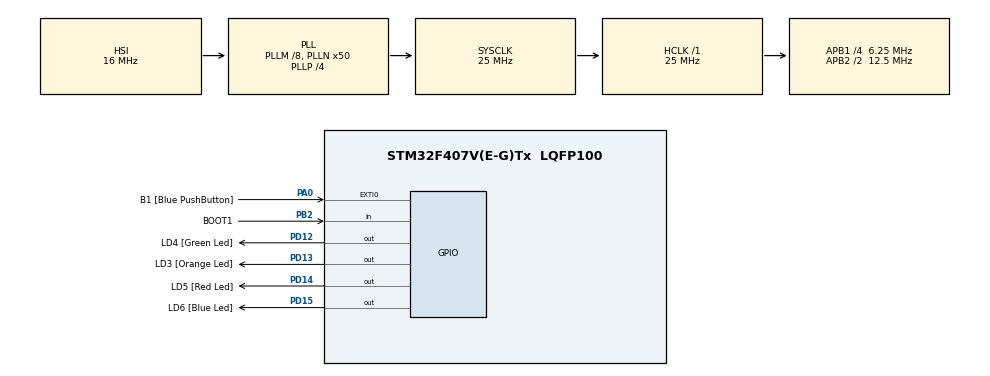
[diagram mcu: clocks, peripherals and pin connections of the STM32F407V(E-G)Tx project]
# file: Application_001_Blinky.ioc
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Mcu.Family=STM32F4
Mcu.Name=STM32F407V(E-G)Tx
Mcu.Package=LQFP100
NVIC.PriorityGroup=NVIC_PRIORITYGROUP_4
NVIC.TIM6_DAC_IRQn=true\:0\:0\:false\:false\:true\:false\:true\:true
NVIC.TimeBase=TIM6_DAC_IRQn
NVIC.TimeBaseIP=TIM6
PA0-WKUP.GPIO_Label=B1 [Blue PushButton]
PA0-WKUP.Signal=GPXTI0
PA13.GPIO_Label=SWDIO
PA13.Signal=SYS_JTMS-SWDIO
PA14.GPIO_Label=SWCLK
PA14.Signal=SYS_JTCK-SWCLK
PB2.GPIO_Label=BOOT1
PB2.GPIO_Mode=GPIO_MODE_INPUT
PB2.GPIO_PuPd=GPIO_NOPULL
PB2.Signal=GPIO_Input
PB3.GPIO_Label=SWO
PB3.Signal=SYS_JTDO-SWO
PC7.GPIO_Label=I2S3_MCK [CS43L22_MCLK]
PC7.GPIO_Mode=GPIO_MODE_AF_PP
PC7.GPIO_PuPd=GPIO_NOPULL
PC7.GPIO_Speed=GPIO_SPEED_FREQ_LOW
PC7.Signal=I2S3_MCK
PD12.GPIO_Label=LD4 [Green Led]
PD12.GPIO_PuPd=GPIO_NOPULL
PD12.GPIO_Speed=GPIO_SPEED_FREQ_LOW
PD12.Signal=GPIO_Output
PD13.GPIO_Label=LD3 [Orange Led]
PD13.GPIO_PuPd=GPIO_NOPULL
PD13.GPIO_Speed=GPIO_SPEED_FREQ_LOW
PD13.Signal=GPIO_Output
PD14.GPIO_Label=LD5 [Red Led]
PD14.GPIO_PuPd=GPIO_NOPULL
PD14.GPIO_Speed=GPIO_SPEED_FREQ_LOW
PD14.Signal=GPIO_Output
PD15.GPIO_Label=LD6 [Blue Led]
PD15.GPIO_PuPd=GPIO_NOPULL
PD15.GPIO_Speed=GPIO_SPEED_FREQ_LOW
PD15.Signal=GPIO_Output
ProjectManager.HeapSize=0x200
ProjectManager.StackSize=0x400
ProjectManager.TargetToolchain=STM32CubeIDE
RCC.48MHZClocksFreq_Value=14285714.285714285
RCC.AHBFreq_Value=25000000
RCC.APB1CLKDivider=RCC_HCLK_DIV4
RCC.APB1Freq_Value=6250000
RCC.APB1TimFreq_Value=12500000
RCC.APB2CLKDivider=RCC_HCLK_DIV2
RCC.APB2Freq_Value=12500000
RCC.APB2TimFreq_Value=25000000
RCC.CortexFreq_Value=25000000
RCC.HCLKFreq_Value=25000000
RCC.HSE_VALUE=8000000
RCC.HSI_VALUE=16000000
RCC.LSE_VALUE=32768
RCC.PLLM=8
RCC.PLLN=50
RCC.PLLP=RCC_PLLP_DIV4
RCC.PLLQ=7
RCC.SYSCLKFreq_VALUE=25000000
RCC.SYSCLKSource=RCC_SYSCLKSOURCE_PLLCLK
RCC.VCOOutputFreq_Value=100000000
VP_SYS_VS_tim6.Mode=TIM6
board=STM32F407G-DISC1

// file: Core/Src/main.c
/* USER CODE BEGIN Header */
/**
  ******************************************************************************
  * @file           : main.c
  * @brief          : Main program body
  ******************************************************************************
  * @attention
  *
  * Copyright (c) 2024 STMicroelectronics.
  * All rights reserved.
  *
  * This software is licensed under terms that can be found in the LICENSE file
  * in the root directory of this software component.
  * If no LICENSE file comes with this software, it is provided AS-IS.
  *
  ******************************************************************************
  */
/* USER CODE END Header */
#include "main.h"

/* USER CODE BEGIN Includes */
#include "FreeRTOS.h"
#include "task.h"
/* USER CODE END Includes */

void SystemClock_Config(void);
static void MX_GPIO_Init(void);
/* USER CODE BEGIN PFP */
void LED_Task( void *pvParameters );
/* USER CODE END PFP */

int main(void)
{

  /* MCU Configuration--------------------------------------------------------*/

  /* Reset of all peripherals, Initializes the Flash interface and the Systick. */
  HAL_Init();

  /* Configure the system clock */
  SystemClock_Config();

  /* Initialize all configured peripherals */
  MX_GPIO_Init();
  /* USER CODE BEGIN 2 */
  xTaskCreate( LED_Task, "LED", 128, NULL, 1, NULL );
  vTaskStartScheduler();
  /* USER CODE END 2 */

  /* Infinite loop */
  while (1)
  {

  }
}

void SystemClock_Config(void)
{
  RCC_OscInitTypeDef RCC_OscInitStruct = {0};
  RCC_ClkInitTypeDef RCC_ClkInitStruct = {0};

  /** Configure the main internal regulator output voltage
  */
  __HAL_RCC_PWR_CLK_ENABLE();
  __HAL_PWR_VOLTAGESCALING_CONFIG(PWR_REGULATOR_VOLTAGE_SCALE1);

  /** Initializes the RCC Oscillators according to the specified parameters
  * in the RCC_OscInitTypeDef structure.
  */
  RCC_OscInitStruct.OscillatorType = RCC_OSCILLATORTYPE_HSI;
  RCC_OscInitStruct.HSIState = RCC_HSI_ON;
  RCC_OscInitStruct.HSICalibrationValue = RCC_HSICALIBRATION_DEFAULT;
  RCC_OscInitStruct.PLL.PLLState = RCC_PLL_ON;
  RCC_OscInitStruct.PLL.PLLSource = RCC_PLLSOURCE_HSI;
  RCC_OscInitStruct.PLL.PLLM = 8;
  RCC_OscInitStruct.PLL.PLLN = 50;
  RCC_OscInitStruct.PLL.PLLP = RCC_PLLP_DIV4;
  RCC_OscInitStruct.PLL.PLLQ = 7;
  if (HAL_RCC_OscConfig(&RCC_OscInitStruct) != HAL_OK)
  {
    Error_Handler();
  }

  /** Initializes the CPU, AHB and APB buses clocks
  */
  RCC_ClkInitStruct.ClockType = RCC_CLOCKTYPE_HCLK|RCC_CLOCKTYPE_SYSCLK
                              |RCC_CLOCKTYPE_PCLK1|RCC_CLOCKTYPE_PCLK2;
  RCC_ClkInitStruct.SYSCLKSource = RCC_SYSCLKSOURCE_PLLCLK;
  RCC_ClkInitStruct.AHBCLKDivider = RCC_SYSCLK_DIV1;
  RCC_ClkInitStruct.APB1CLKDivider = RCC_HCLK_DIV4;
  RCC_ClkInitStruct.APB2CLKDivider = RCC_HCLK_DIV2;

  if (HAL_RCC_ClockConfig(&RCC_ClkInitStruct, FLASH_LATENCY_0) != HAL_OK)
  {
    Error_Handler();
  }
}

static void MX_GPIO_Init(void)
{
  GPIO_InitTypeDef GPIO_InitStruct = {0};

  /* GPIO Ports Clock Enable */
  __HAL_RCC_GPIOA_CLK_ENABLE();
  __HAL_RCC_GPIOB_CLK_ENABLE();
  __HAL_RCC_GPIOD_CLK_ENABLE();
  __HAL_RCC_GPIOC_CLK_ENABLE();

  /*Configure GPIO pin Output Level */
  HAL_GPIO_WritePin(GPIOD, LD4_Pin|LD3_Pin|LD5_Pin|LD6_Pin, GPIO_PIN_RESET);

  /*Configure GPIO pin : B1_Pin */
  GPIO_InitStruct.Pin = B1_Pin;
  GPIO_InitStruct.Mode = GPIO_MODE_IT_RISING;
  GPIO_InitStruct.Pull = GPIO_NOPULL;
  HAL_GPIO_Init(B1_GPIO_Port, &GPIO_InitStruct);

  /*Configure GPIO pin : BOOT1_Pin */
  GPIO_InitStruct.Pin = BOOT1_Pin;
  GPIO_InitStruct.Mode = GPIO_MODE_INPUT;
  GPIO_InitStruct.Pull = GPIO_NOPULL;
  HAL_GPIO_Init(BOOT1_GPIO_Port, &GPIO_InitStruct);

  /*Configure GPIO pins : LD4_Pin LD3_Pin LD5_Pin LD6_Pin */
  GPIO_InitStruct.Pin = LD4_Pin|LD3_Pin|LD5_Pin|LD6_Pin;
  GPIO_InitStruct.Mode = GPIO_MODE_OUTPUT_PP;
  GPIO_InitStruct.Pull = GPIO_NOPULL;
  GPIO_InitStruct.Speed = GPIO_SPEED_FREQ_LOW;
  HAL_GPIO_Init(GPIOD, &GPIO_InitStruct);

  /*Configure GPIO pin : I2S3_MCK_Pin */
  GPIO_InitStruct.Pin = I2S3_MCK_Pin;
  GPIO_InitStruct.Mode = GPIO_MODE_AF_PP;
  GPIO_InitStruct.Pull = GPIO_NOPULL;
  GPIO_InitStruct.Speed = GPIO_SPEED_FREQ_LOW;
  GPIO_InitStruct.Alternate = GPIO_AF6_SPI3;
  HAL_GPIO_Init(I2S3_MCK_GPIO_Port, &GPIO_InitStruct);

}

/* USER CODE BEGIN 4 */
void LED_Task( void *pvParameters )
{
  for ( ; ; )
  {
    HAL_GPIO_TogglePin( GPIOD, GPIO_PIN_15 );

    vTaskDelay( pdMS_TO_TICKS( 500 ) );
  }
}
/* USER CODE END 4 */

void HAL_TIM_PeriodElapsedCallback(TIM_HandleTypeDef *htim)
{
  if (htim->Instance == TIM6) {
    HAL_IncTick();
  }
}

void Error_Handler(void)
{
  __disable_irq();
  while (1)
  {
  }
}
